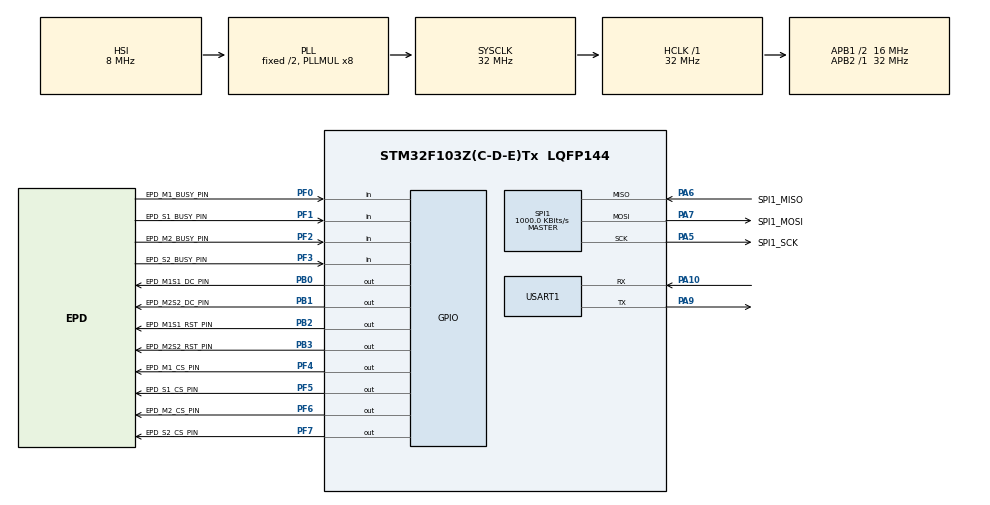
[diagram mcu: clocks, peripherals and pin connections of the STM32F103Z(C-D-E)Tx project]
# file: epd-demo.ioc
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Mcu.Family=STM32F1
Mcu.Name=STM32F103Z(C-D-E)Tx
Mcu.Package=LQFP144
NVIC.PriorityGroup=NVIC_PRIORITYGROUP_4
PA10.Mode=Asynchronous
PA10.Signal=USART1_RX
PA13.Mode=Serial_Wire
PA13.Signal=SYS_JTMS-SWDIO
PA14.Mode=Serial_Wire
PA14.Signal=SYS_JTCK-SWCLK
PA5.GPIO_Label=SPI1_SCK
PA5.Mode=Full_Duplex_Master
PA5.Signal=SPI1_SCK
PA6.GPIO_Label=SPI1_MISO
PA6.Mode=Full_Duplex_Master
PA6.Signal=SPI1_MISO
PA7.GPIO_Label=SPI1_MOSI
PA7.Mode=Full_Duplex_Master
PA7.Signal=SPI1_MOSI
PA9.Mode=Asynchronous
PA9.Signal=USART1_TX
PB0.GPIO_Label=EPD_M1S1_DC_PIN
PB0.Signal=GPIO_Output
PB1.GPIO_Label=EPD_M2S2_DC_PIN
PB1.Signal=GPIO_Output
PB2.GPIO_Label=EPD_M1S1_RST_PIN
PB2.Signal=GPIO_Output
PB3.GPIO_Label=EPD_M2S2_RST_PIN
PB3.Signal=GPIO_Output
PF0.GPIO_Label=EPD_M1_BUSY_PIN
PF0.Signal=GPIO_Input
PF1.GPIO_Label=EPD_S1_BUSY_PIN
PF1.Signal=GPIO_Input
PF2.GPIO_Label=EPD_M2_BUSY_PIN
PF2.Signal=GPIO_Input
PF3.GPIO_Label=EPD_S2_BUSY_PIN
PF3.Signal=GPIO_Input
PF4.GPIO_Label=EPD_M1_CS_PIN
PF4.Signal=GPIO_Output
PF5.GPIO_Label=EPD_S1_CS_PIN
PF5.Signal=GPIO_Output
PF6.GPIO_Label=EPD_M2_CS_PIN
PF6.Signal=GPIO_Output
PF7.GPIO_Label=EPD_S2_CS_PIN
PF7.Signal=GPIO_Output
ProjectManager.HeapSize=0x9000
ProjectManager.StackSize=0x1000
ProjectManager.TargetToolchain=MDK-ARM V5
RCC.AHBFreq_Value=32000000
RCC.APB1CLKDivider=RCC_HCLK_DIV2
RCC.APB1Freq_Value=16000000
RCC.APB1TimFreq_Value=32000000
RCC.APB2Freq_Value=32000000
RCC.APB2TimFreq_Value=32000000
RCC.HCLKFreq_Value=32000000
RCC.PLLMUL=RCC_PLL_MUL8
RCC.SYSCLKFreq_VALUE=32000000
RCC.SYSCLKSource=RCC_SYSCLKSOURCE_PLLCLK
RCC.USBFreq_Value=32000000
SPI1.BaudRatePrescaler=SPI_BAUDRATEPRESCALER_32
SPI1.CalculateBaudRate=1000.0 KBits/s
SPI1.Direction=SPI_DIRECTION_2LINES
SPI1.Mode=SPI_MODE_MASTER
SPI1.VirtualType=VM_MASTER
USART1.VirtualMode=VM_ASYNC
board=epd5in83-demo

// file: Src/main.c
/* USER CODE BEGIN Header */
/**
  ******************************************************************************
  * @file           : main.c
  * @brief          : Main program body
  ******************************************************************************
  * @attention
  *
  * <h2><center>&copy; Copyright (c) 2019 STMicroelectronics.
  * All rights reserved.</center></h2>
  *
  * This software component is licensed by ST under BSD 3-Clause license,
  * the "License"; You may not use this file except in compliance with the
  * License. You may obtain a copy of the License at:
  *                        opensource.org/licenses/BSD-3-Clause
  *
  ******************************************************************************
  */
/* USER CODE END Header */

#include "main.h"
#include "spi.h"
#include "usart.h"
#include "gpio.h"

/* USER CODE BEGIN Includes */
#include "DEV_Config.h"
#include "EPD_12in48.h"
#include "GUI_Paint.h"
#include "imagedata.h"
#include <stdlib.h>
#include "test.h"
/* USER CODE END Includes */

void SystemClock_Config(void);

/* USER CODE BEGIN 0 */
int Version;
/* USER CODE END 0 */

int main(void)
{

  /* MCU Configuration--------------------------------------------------------*/

  /* Reset of all peripherals, Initializes the Flash interface and the Systick. */
  HAL_Init();

  /* Configure the system clock */
  SystemClock_Config();

  /* Initialize all configured peripherals */
  MX_GPIO_Init();
  MX_USART1_UART_Init();
  MX_SPI1_Init();
  /* USER CODE BEGIN 2 */

	/*Select the corresponding routine according to the actual screen*/
	//EPD_12in48 is black and white
	//EPD_12in48B is black and white red

  /* USER CODE END 2 */

  /* Infinite loop */
  while (1)
  {

    /* USER CODE BEGIN 3 */
	//EPD_12in48_test();
	//EPD_12in48B_test();
	EPD_12in48B_V2_test();
	DEV_Delay_ms(9000);
  }
  /* USER CODE END 3 */
}

void SystemClock_Config(void)
{
  RCC_OscInitTypeDef RCC_OscInitStruct = {0};
  RCC_ClkInitTypeDef RCC_ClkInitStruct = {0};

  /** Initializes the CPU, AHB and APB busses clocks
  */
  RCC_OscInitStruct.OscillatorType = RCC_OSCILLATORTYPE_HSI;
  RCC_OscInitStruct.HSIState = RCC_HSI_ON;
  RCC_OscInitStruct.HSICalibrationValue = RCC_HSICALIBRATION_DEFAULT;
  RCC_OscInitStruct.PLL.PLLState = RCC_PLL_ON;
  RCC_OscInitStruct.PLL.PLLSource = RCC_PLLSOURCE_HSI_DIV2;
  RCC_OscInitStruct.PLL.PLLMUL = RCC_PLL_MUL8;
  if (HAL_RCC_OscConfig(&RCC_OscInitStruct) != HAL_OK)
  {
    Error_Handler();
  }
  /** Initializes the CPU, AHB and APB busses clocks
  */
  RCC_ClkInitStruct.ClockType = RCC_CLOCKTYPE_HCLK|RCC_CLOCKTYPE_SYSCLK
                              |RCC_CLOCKTYPE_PCLK1|RCC_CLOCKTYPE_PCLK2;
  RCC_ClkInitStruct.SYSCLKSource = RCC_SYSCLKSOURCE_PLLCLK;
  RCC_ClkInitStruct.AHBCLKDivider = RCC_SYSCLK_DIV1;
  RCC_ClkInitStruct.APB1CLKDivider = RCC_HCLK_DIV2;
  RCC_ClkInitStruct.APB2CLKDivider = RCC_HCLK_DIV1;

  if (HAL_RCC_ClockConfig(&RCC_ClkInitStruct, FLASH_LATENCY_1) != HAL_OK)
  {
    Error_Handler();
  }
}

void Error_Handler(void)
{
}

/************************ (C) COPYRIGHT STMicroelectronics *****END OF FILE****/
